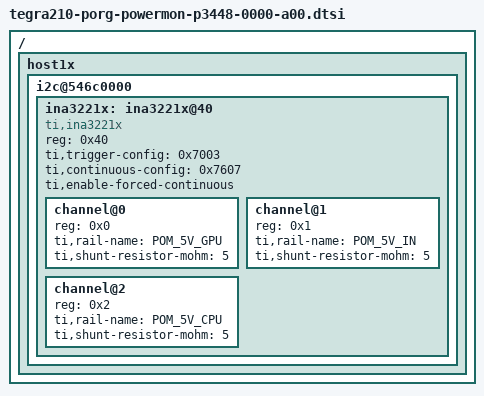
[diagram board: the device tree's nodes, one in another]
/*
 * Copyright (c) 2018, NVIDIA CORPORATION.  All rights reserved.
 *
 * This program is free software; you can redistribute it and/or modify
 * it under the terms of the GNU General Public License as published by
 * the Free Software Foundation; either version 2 of the License, or
 * (at your option) any later version.
 *
 * This program is distributed in the hope that it will be useful, but WITHOUT
 * ANY WARRANTY; without even the implied warranty of MERCHANTABILITY or
 * FITNESS FOR A PARTICULAR PURPOSE.  See the GNU General Public License for
 * more details.
 *
 * You should have received a copy of the GNU General Public License along
 * with this program; if not, write to the Free Software Foundation, Inc.,
 * 51 Franklin Street, Fifth Floor, Boston, MA  02110-1301, USA.
 */
/ {
	host1x {
		i2c@546c0000 {
			ina3221x: ina3221x@40 {
				compatible = "ti,ina3221x";
				reg = <0x40>;
				status="okay";
				ti,trigger-config = <0x7003>;
				ti,continuous-config = <0x7607>;
				ti,enable-forced-continuous;
				#io-channel-cells = <1>;
				#address-cells = <1>;
				#size-cells = <0>;
				channel@0 {
					reg = <0x0>;
					ti,rail-name = "POM_5V_GPU";
					ti,shunt-resistor-mohm = <5>;
				};

				channel@1 {
					reg = <0x1>;
					ti,rail-name = "POM_5V_IN";
					ti,shunt-resistor-mohm = <5>;
				};

				channel@2 {
					reg = <0x2>;
					ti,rail-name = "POM_5V_CPU";
					ti,shunt-resistor-mohm = <5>;
				};
			};
		};
	};
};
